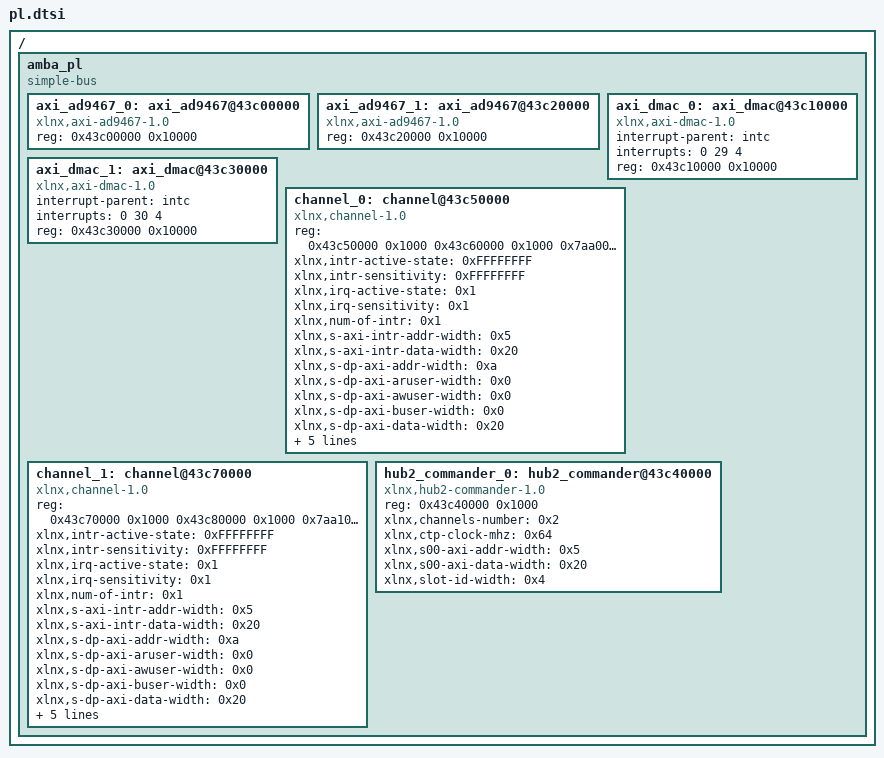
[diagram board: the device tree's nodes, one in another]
/*
 * CAUTION: This file is automatically generated by Xilinx.
 * Version: HSI 2015.4
 * Today is: Wed Mar 14 15:48:56 2018
*/


/ {
	amba_pl: amba_pl {
		#address-cells = <1>;
		#size-cells = <1>;
		compatible = "simple-bus";
		ranges ;
		axi_ad9467_0: axi_ad9467@43c00000 {
			compatible = "xlnx,axi-ad9467-1.0";
			reg = <0x43c00000 0x10000>;
		};
		axi_ad9467_1: axi_ad9467@43c20000 {
			compatible = "xlnx,axi-ad9467-1.0";
			reg = <0x43c20000 0x10000>;
		};
		axi_dmac_0: axi_dmac@43c10000 {
			compatible = "xlnx,axi-dmac-1.0";
			interrupt-parent = <&intc>;
			interrupts = <0 29 4>;
			reg = <0x43c10000 0x10000>;
		};
		axi_dmac_1: axi_dmac@43c30000 {
			compatible = "xlnx,axi-dmac-1.0";
			interrupt-parent = <&intc>;
			interrupts = <0 30 4>;
			reg = <0x43c30000 0x10000>;
		};
		channel_0: channel@43c50000 {
			compatible = "xlnx,channel-1.0";
			reg = <0x43c50000 0x1000 0x43c60000 0x1000 0x7aa00000 0x1000>;
			xlnx,intr-active-state = <0xFFFFFFFF>;
			xlnx,intr-sensitivity = <0xFFFFFFFF>;
			xlnx,irq-active-state = <0x1>;
			xlnx,irq-sensitivity = <0x1>;
			xlnx,num-of-intr = <0x1>;
			xlnx,s-axi-intr-addr-width = <0x5>;
			xlnx,s-axi-intr-data-width = <0x20>;
			xlnx,s-dp-axi-addr-width = <0xa>;
			xlnx,s-dp-axi-aruser-width = <0x0>;
			xlnx,s-dp-axi-awuser-width = <0x0>;
			xlnx,s-dp-axi-buser-width = <0x0>;
			xlnx,s-dp-axi-data-width = <0x20>;
			xlnx,s-dp-axi-id-width = <0x0>;
			xlnx,s-dp-axi-ruser-width = <0x0>;
			xlnx,s-dp-axi-wuser-width = <0x0>;
			xlnx,s-sp-axi-addr-width = <0x7>;
			xlnx,s-sp-axi-data-width = <0x20>;
		};
		channel_1: channel@43c70000 {
			compatible = "xlnx,channel-1.0";
			reg = <0x43c70000 0x1000 0x43c80000 0x1000 0x7aa10000 0x1000>;
			xlnx,intr-active-state = <0xFFFFFFFF>;
			xlnx,intr-sensitivity = <0xFFFFFFFF>;
			xlnx,irq-active-state = <0x1>;
			xlnx,irq-sensitivity = <0x1>;
			xlnx,num-of-intr = <0x1>;
			xlnx,s-axi-intr-addr-width = <0x5>;
			xlnx,s-axi-intr-data-width = <0x20>;
			xlnx,s-dp-axi-addr-width = <0xa>;
			xlnx,s-dp-axi-aruser-width = <0x0>;
			xlnx,s-dp-axi-awuser-width = <0x0>;
			xlnx,s-dp-axi-buser-width = <0x0>;
			xlnx,s-dp-axi-data-width = <0x20>;
			xlnx,s-dp-axi-id-width = <0x0>;
			xlnx,s-dp-axi-ruser-width = <0x0>;
			xlnx,s-dp-axi-wuser-width = <0x0>;
			xlnx,s-sp-axi-addr-width = <0x7>;
			xlnx,s-sp-axi-data-width = <0x20>;
		};
		hub2_commander_0: hub2_commander@43c40000 {
			compatible = "xlnx,hub2-commander-1.0";
			reg = <0x43c40000 0x1000>;
			xlnx,channels-number = <0x2>;
			xlnx,ctp-clock-mhz = <0x64>;
			xlnx,s00-axi-addr-width = <0x5>;
			xlnx,s00-axi-data-width = <0x20>;
			xlnx,slot-id-width = <0x4>;
		};
	};
};
